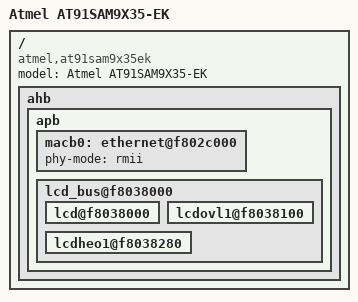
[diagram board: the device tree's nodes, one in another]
/*
 * at91sam9x35ek.dts - Device Tree file for AT91SAM9X35-EK board
 *
 *  Copyright (C) 2012 Atmel,
 *                2012 Nicolas Ferre <nicolas.ferre@atmel.com>
 *
 * Licensed under GPLv2 or later.
 */
/dts-v1/;
#include "at91sam9x35.dtsi"
#include "at91sam9x5ek.dtsi"

/ {
	model = "Atmel AT91SAM9X35-EK";
	compatible = "atmel,at91sam9x35ek", "atmel,at91sam9x5ek", "atmel,at91sam9x5", "atmel,at91sam9";

	ahb {
		apb {
			macb0: ethernet@f802c000 {
				phy-mode = "rmii";
				status = "okay";
			};

			lcd_bus@f8038000 {
				status = "okay";

				lcd@f8038000 {
					status = "okay";
				};

				lcdovl1@f8038100 {
					status = "okay";
				};

				lcdheo1@f8038280 {
					status = "okay";
				};
			};
		};
	};
};
